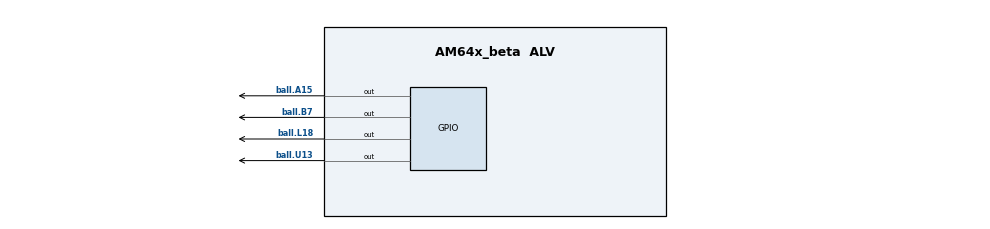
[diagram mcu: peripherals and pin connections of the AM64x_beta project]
/**
 * @cliArgs --device "AM64x_beta" --package "ALV" --part "Default" --context "r5fss0-0" --product "MCU_PLUS_SDK_AM64x@08.01.00"
 * @versions {"tool":"1.11.0+2225"}
 */

/**
 * Import the modules used in this configuration.
 */
const eeprom     = scripting.addModule("/board/eeprom/eeprom", {}, false);
const eeprom1    = eeprom.addInstance();
const led        = scripting.addModule("/board/led/led", {}, false);
const led1       = led.addInstance();
const led2       = led.addInstance();
const led3       = led.addInstance();
const led4       = led.addInstance();
const led5       = led.addInstance();
const gpio       = scripting.addModule("/drivers/gpio/gpio", {}, false);
const gpio1      = gpio.addInstance();
const gpio2      = gpio.addInstance();
const gpio3      = gpio.addInstance();
const gpio4      = gpio.addInstance();
const i2c        = scripting.addModule("/drivers/i2c/i2c", {}, false);
const i2c1       = i2c.addInstance();
const i2c2       = i2c.addInstance();
const ipc        = scripting.addModule("/drivers/ipc/ipc");
const ospi       = scripting.addModule("/drivers/ospi/ospi", {}, false);
const ospi1      = ospi.addInstance();
const uart       = scripting.addModule("/drivers/uart/uart", {}, false);
const uart1      = uart.addInstance();
const ethercat   = scripting.addModule("/industrial_comms/ethercat/ethercat", {}, false);
const ethercat1  = ethercat.addInstance();
const clock      = scripting.addModule("/kernel/dpl/clock");
const debug_log  = scripting.addModule("/kernel/dpl/debug_log");
const mpu_armv7  = scripting.addModule("/kernel/dpl/mpu_armv7", {}, false);
const mpu_armv71 = mpu_armv7.addInstance();
const mpu_armv72 = mpu_armv7.addInstance();
const mpu_armv73 = mpu_armv7.addInstance();
const mpu_armv74 = mpu_armv7.addInstance();
const mpu_armv75 = mpu_armv7.addInstance();
const timer      = scripting.addModule("/kernel/dpl/timer", {}, false);
const timer1     = timer.addInstance();

/**
 * Write custom configuration values to the imported modules.
 */
eeprom1.$name = "CONFIG_EEPROM0";

led1.$name = "CONFIG_LED0";
led1.name  = "PCA9533D";

led2.$name   = "CONFIG_LED_ERROR";
led2.ioIndex = 16;

led3.$name = "CONFIG_LED_STATUS";

led4.$name   = "CONFIG_PHY0_RESET";
led4.ioIndex = 3;

led5.$name = "CONFIG_PHY1_RESET";

led2.peripheralDriver          = gpio1;
gpio1.$name                    = "CONFIG_GPIO0";
gpio1.pinDir                   = "OUTPUT";
gpio1.useMcuDomainPeripherals  = true;
gpio1.MCU_GPIO.gpioPin.$assign = "ball.B7";

gpio2.$name                = "CONFIG_GPIO1";
led3.peripheralDriver      = gpio2;
gpio2.GPIO.gpioPin.$assign = "ball.L18";

gpio3.$name                = "CONFIG_GPIO2";
led4.peripheralDriver      = gpio3;
gpio3.pinDir               = "OUTPUT";
gpio3.GPIO.gpioPin.pu_pd   = "pd";
gpio3.GPIO.gpioPin.rx      = false;
gpio3.GPIO.gpioPin.$assign = "ball.U13";

gpio4.$name                = "CONFIG_GPIO3";
led5.peripheralDriver      = gpio4;
gpio4.pinDir               = "OUTPUT";
gpio4.GPIO.gpioPin.pu_pd   = "pd";
gpio4.GPIO.gpioPin.rx      = false;
gpio4.GPIO.gpioPin.$assign = "ball.A15";

i2c1.$name            = "CONFIG_I2C1";
led1.peripheralDriver = i2c1;

i2c2.$name               = "CONFIG_I2C0";
eeprom1.peripheralDriver = i2c2;

ipc.r5fss0_1 = "NONE";
ipc.r5fss1_0 = "notify";
ipc.r5fss1_1 = "NONE";
ipc.m4fss0_0 = "NONE";

ospi1.$name        = "CONFIG_OSPI0";
ospi1.inputClkFreq = 200000000;

uart1.$name = "CONFIG_UART_CONSOLE";

ethercat1.$name                                 = "CONFIG_ETHERCAT0";
ethercat1.instance                              = "ICSSG1";
ethercat1.ethphy[0].$name                       = "CONFIG_ETHPHY0";
ethercat1.ethphy[0].mdioPort                    = 1;
ethercat1.ethphy[1].$name                       = "CONFIG_ETHPHY1";
ethercat1.ethphy[1].mdioPort                    = 2;
ethercat1.PRU_ICSSG1_IEP.EDC_LATCH_IN0.rx       = false;
ethercat1.PRU_ICSSG1_IEP.EDC_LATCH_IN0.$used    = false;
ethercat1.PRU_ICSSG1_IEP.EDC_LATCH_IN1.rx       = false;
ethercat1.PRU_ICSSG1_IEP.EDC_LATCH_IN1.$used    = false;
ethercat1.PRU_ICSSG1_IEP.EDC_SYNC_OUT0.$used    = false;
ethercat1.PRU_ICSSG1_IEP.EDC_SYNC_OUT1.$used    = false;
ethercat1.PRU_ICSSG1_MII_G_RT.MII1_RXLINK.pu_pd = "pd";

const pruicss  = scripting.addModule("/drivers/pruicss/pruicss", {}, false);
const pruicss1 = pruicss.addInstance({}, false);
pruicss1.$name = "CONFIG_PRU_ICSS1";
ethercat1.icss = pruicss1;

debug_log.enableLogZoneInfo = true;

mpu_armv71.$name        = "CONFIG_MPU_REGION0";
mpu_armv71.size         = 31;
mpu_armv71.attributes   = "Device";
mpu_armv71.allowExecute = false;

mpu_armv72.$name             = "CONFIG_MPU_REGION1";
mpu_armv72.size              = 15;
mpu_armv72.accessPermissions = "Supervisor RD+WR, User RD";

mpu_armv73.$name             = "CONFIG_MPU_REGION2";
mpu_armv73.baseAddr          = 0x41010000;
mpu_armv73.size              = 15;
mpu_armv73.accessPermissions = "Supervisor RD+WR, User RD";

mpu_armv74.$name             = "CONFIG_MPU_REGION3";
mpu_armv74.baseAddr          = 0x70000000;
mpu_armv74.size              = 21;
mpu_armv74.accessPermissions = "Supervisor RD+WR, User RD";

mpu_armv75.$name      = "CONFIG_MPU_REGION4";
mpu_armv75.baseAddr   = 0x70180000;
mpu_armv75.size       = 18;
mpu_armv75.attributes = "Device";

timer1.$name         = "CONFIG_TIMER0";
timer1.usecPerTick   = 100;
timer1.startTimer    = true;
timer1.timerCallback = "OSAL_FREERTOS_callbackTimer";
timer1.TIMER.$assign = "DMTIMER0";

/**
 * Pinmux solution for unlocked pins/peripherals. This ensures that minor changes to the automatic solver in a future
 * version of the tool will not impact the pinmux you originally saw.  These lines can be completely deleted in order to
 * re-solve from scratch.
 */
gpio1.MCU_GPIO.$suggestSolution                            = "MCU_GPIO0";
gpio2.GPIO.$suggestSolution                                = "GPIO0";
gpio3.GPIO.$suggestSolution                                = "GPIO0";
gpio4.GPIO.$suggestSolution                                = "GPIO1";
i2c1.I2C.$suggestSolution                                  = "I2C1";
i2c1.I2C.SCL.$suggestSolution                              = "ball.C18";
i2c1.I2C.SDA.$suggestSolution                              = "ball.B19";
i2c2.I2C.$suggestSolution                                  = "I2C0";
i2c2.I2C.SCL.$suggestSolution                              = "ball.A18";
i2c2.I2C.SDA.$suggestSolution                              = "ball.B18";
ospi1.OSPI.$suggestSolution                                = "OSPI0";
ospi1.OSPI.CLK.$suggestSolution                            = "ball.N20";
ospi1.OSPI.CSn0.$suggestSolution                           = "ball.L19";
ospi1.OSPI.DQS.$suggestSolution                            = "ball.N19";
ospi1.OSPI.D7.$suggestSolution                             = "ball.M17";
ospi1.OSPI.D6.$suggestSolution                             = "ball.N18";
ospi1.OSPI.D5.$suggestSolution                             = "ball.P20";
ospi1.OSPI.D4.$suggestSolution                             = "ball.P21";
ospi1.OSPI.D3.$suggestSolution                             = "ball.M21";
ospi1.OSPI.D2.$suggestSolution                             = "ball.M20";
ospi1.OSPI.D1.$suggestSolution                             = "ball.M18";
ospi1.OSPI.D0.$suggestSolution                             = "ball.M19";
uart1.UART.$suggestSolution                                = "USART0";
uart1.UART.RXD.$suggestSolution                            = "ball.D15";
uart1.UART.TXD.$suggestSolution                            = "ball.C16";
ethercat1.PRU_ICSSG1_MDIO.$suggestSolution                 = "PRU_ICSSG1_MDIO0";
ethercat1.PRU_ICSSG1_MDIO.MDC.$suggestSolution             = "ball.Y6";
ethercat1.PRU_ICSSG1_MDIO.MDIO.$suggestSolution            = "ball.AA6";
ethercat1.PRU_ICSSG1_IEP.$suggestSolution                  = "PRU_ICSSG1_IEP0";
ethercat1.PRU_ICSSG1_MII_G_RT.$suggestSolution             = "PRU_ICSSG1_MII_G_RT";
ethercat1.PRU_ICSSG1_MII_G_RT.MII0_RXD0.$suggestSolution   = "ball.Y7";
ethercat1.PRU_ICSSG1_MII_G_RT.MII0_RXD1.$suggestSolution   = "ball.U8";
ethercat1.PRU_ICSSG1_MII_G_RT.MII0_RXD2.$suggestSolution   = "ball.W8";
ethercat1.PRU_ICSSG1_MII_G_RT.MII0_RXD3.$suggestSolution   = "ball.V8";
ethercat1.PRU_ICSSG1_MII_G_RT.MII0_RXDV.$suggestSolution   = "ball.Y8";
ethercat1.PRU_ICSSG1_MII_G_RT.MII0_RXER.$suggestSolution   = "ball.V13";
ethercat1.PRU_ICSSG1_MII_G_RT.MII0_RXLINK.$suggestSolution = "ball.W13";
ethercat1.PRU_ICSSG1_MII_G_RT.MII0_TXD0.$suggestSolution   = "ball.AA8";
ethercat1.PRU_ICSSG1_MII_G_RT.MII0_TXD1.$suggestSolution   = "ball.U9";
ethercat1.PRU_ICSSG1_MII_G_RT.MII0_TXD2.$suggestSolution   = "ball.W9";
ethercat1.PRU_ICSSG1_MII_G_RT.MII0_TXD3.$suggestSolution   = "ball.AA9";
ethercat1.PRU_ICSSG1_MII_G_RT.MII0_TXEN.$suggestSolution   = "ball.Y9";
ethercat1.PRU_ICSSG1_MII_G_RT.MII1_RXD0.$suggestSolution   = "ball.W11";
ethercat1.PRU_ICSSG1_MII_G_RT.MII1_RXD1.$suggestSolution   = "ball.V11";
ethercat1.PRU_ICSSG1_MII_G_RT.MII1_RXD2.$suggestSolution   = "ball.AA12";
ethercat1.PRU_ICSSG1_MII_G_RT.MII1_RXD3.$suggestSolution   = "ball.Y12";
ethercat1.PRU_ICSSG1_MII_G_RT.MII1_RXDV.$suggestSolution   = "ball.W12";
ethercat1.PRU_ICSSG1_MII_G_RT.MII1_RXER.$suggestSolution   = "ball.AA13";
ethercat1.PRU_ICSSG1_MII_G_RT.MII1_RXLINK.$suggestSolution = "ball.U12";
ethercat1.PRU_ICSSG1_MII_G_RT.MII1_TXD0.$suggestSolution   = "ball.AA10";
ethercat1.PRU_ICSSG1_MII_G_RT.MII1_TXD1.$suggestSolution   = "ball.V10";
ethercat1.PRU_ICSSG1_MII_G_RT.MII1_TXD2.$suggestSolution   = "ball.U10";
ethercat1.PRU_ICSSG1_MII_G_RT.MII1_TXD3.$suggestSolution   = "ball.AA11";
ethercat1.PRU_ICSSG1_MII_G_RT.MII1_TXEN.$suggestSolution   = "ball.Y11";
ethercat1.PRU_ICSSG1_MII_G_RT.MII_MR0_CLK.$suggestSolution = "ball.AA7";
ethercat1.PRU_ICSSG1_MII_G_RT.MII_MR1_CLK.$suggestSolution = "ball.U11";
ethercat1.PRU_ICSSG1_MII_G_RT.MII_MT0_CLK.$suggestSolution = "ball.V9";
ethercat1.PRU_ICSSG1_MII_G_RT.MII_MT1_CLK.$suggestSolution = "ball.Y10";
